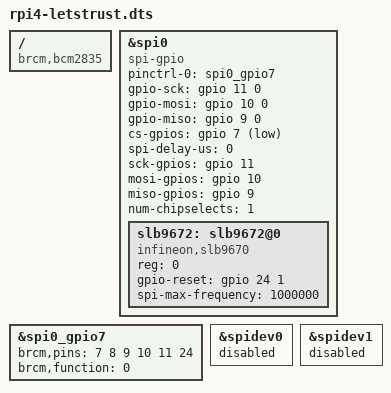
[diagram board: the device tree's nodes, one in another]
/dts-v1/;
/plugin/;

/ {
	compatible = "brcm,bcm2835", "brcm,bcm2708", "brcm,bcm2709";

	fragment@0 {
		target = <&spi0>;
		__overlay__ {
			compatible = "spi-gpio";
			pinctrl-names = "default";
			pinctrl-0 = <&spi0_gpio7>;
			#address-cells = <1>;
			#size-cells = <0>;
			status = "okay";

			/* U-Boot soft-SPI properties */
			gpio-sck = <&gpio 11 0>;
			gpio-mosi = <&gpio 10 0>;
			gpio-miso = <&gpio 9 0>;
			cs-gpios = <&gpio 7 1>;
			spi-delay-us = <0>;

			/* Linux spi-gpio properties */
			sck-gpios = <&gpio 11 0>;
			mosi-gpios = <&gpio 10 0>;
			miso-gpios = <&gpio 9 0>;
			num-chipselects = <1>;

			slb9672: slb9672@0 {
				compatible = "infineon,slb9670", "tis,tpm2-spi", "tcg,tpm_tis-spi";
				reg = <0>;
				gpio-reset = <&gpio 24 1>;
				#address-cells = <1>;
				#size-cells = <0>;
				status = "okay";
				spi-max-frequency = <1000000>;
			};
		};
	};

	fragment@1 {
		target = <&spi0_gpio7>;
		__overlay__ {
			brcm,pins = <7 8 9 10 11 24>;
			brcm,function = <0>;
		};
	};

	fragment@2 {
		target = <&spidev0>;
		__overlay__ {
			status = "disabled";
		};
	};

	fragment@3 {
		target = <&spidev1>;
		__overlay__ {
			status = "disabled";
		};
	};
};
